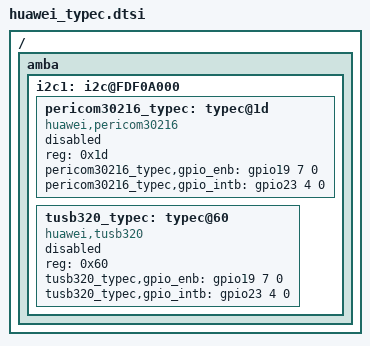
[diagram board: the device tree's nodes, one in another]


/{
	amba{
		i2c1: i2c@FDF0A000 {
			pericom30216_typec: typec@1d {
				compatible = "huawei,pericom30216";
				reg = <0x1d>;
				pericom30216_typec,gpio_enb = <&gpio19 7 0>;
				pericom30216_typec,gpio_intb = <&gpio23 4 0>;
				status = "disable";
			};

			tusb320_typec: typec@60 {
				compatible = "huawei,tusb320";
				reg = <0x60>;
				tusb320_typec,gpio_enb = <&gpio19 7 0>;
				tusb320_typec,gpio_intb = <&gpio23 4 0>;
				status = "disable";
			};
		};
	};
};
